# arp32_control register map
Vendor: Texas Instruments
Peripheral module from a debugger description file (folder ihwa).
Registers are 32-bit, access not given, no defined reset value unless marked. A register's access mark holds for its fields unless they carry their own. Offsets are as the file gives them; lines under a group give offsets from that group; [hi:lo] are bit positions; {n}, {i} and the like mark numbered series; 'fields as' and 'values as' point back to an identical list; <NAME> marks a mode.

## Control — Control Registers
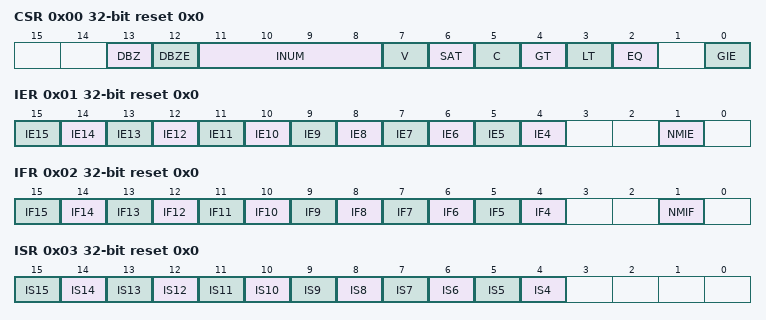
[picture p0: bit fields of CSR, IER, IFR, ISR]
0x00 CSR rw reset 0x0 — Control Status Register
  [13] DBZ — Divide by Zero
  [12] DBZE — Divide by Zero Enable
  [11:8] INUM — Interrupt Number
  [7] V — Overflow Bit
  [6] SAT — Saturation Bit
  [5] C — Carry Bit
  [4] GT — Greater Than Bit
  [3] LT — Less Than Bit
  [2] EQ — Equal Bit
  [0] GIE — Global Interrupt Enable
0x01 IER rw reset 0x0 — Interrupt Enable Register
  [n] IE{n} (n=4..15) — Enable Bit for INT{n}
  [1] NMIE — Enable Bit for NMI
0x02 IFR rw reset 0x0 — Interrupt Flag Register
  [n] IF{n} (n=4..15) — Flag Bit for INT{n}
  [1] NMIF — Flag Bit for NMI
0x03 ISR wo reset 0x0 — Interrupt Set Register
  [n] IS{n} (n=4..15) — Set Bit for INT{n}
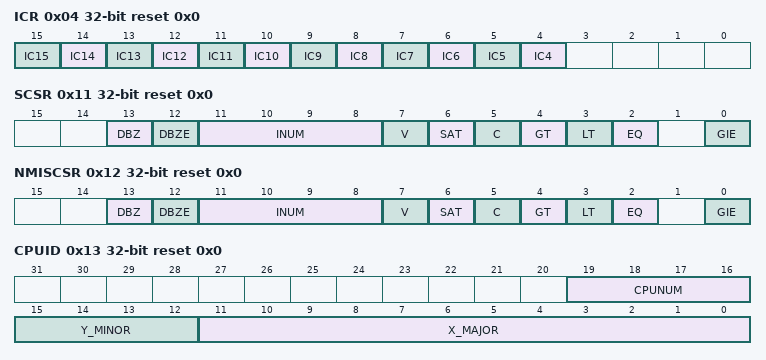
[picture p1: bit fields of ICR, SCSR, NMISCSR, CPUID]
0x04 ICR wo reset 0x0 — Interrupt Clear Register
  [n] IC{n} (n=4..15) — Clear Bit for INT{n}
0x05 NRP — NMI Return Pointer (half word address)
0x06 IRP — Interrupt Return Pointer (half word address)
0x07 SP — Stack Pointer (byte address)
0x08 GDP — Global Data Pointer (byte address)
0x09 LR — Link Register (half word address)
0x0A LSA0 — Loop 0 Start Address (byte address)
0x0B LEA0 — Loop 0 End Address (byte address)
0x0C LCNT0 — Loop 0 Iteration Count
0x0D LSA1 — Loop 1 Start Address (byte address)
0x0E LEA1 — Loop 1 End Address (byte address)
0x0F LCNT1 — Loop 1 Iteration Count
0x10 LCNT0RLD — Loop 0 Iteration Count Reload Value
0x11 SCSR rw reset 0x0 — Shadow CSR
  [13] DBZ — Shadow Copy of CSR:DBZ
  [12] DBZE — Shadow Copy of CSR:DBZE
  [11:8] INUM — Shadow Copy of CSR:INUM
  [7] V — Shadow Copy of CSR:V
  [6] SAT — Shadow Copy of CSR:SAT
  [5] C — Shadow Copy of CSR:C
  [4] GT — Shadow Copy of CSR:GT
  [3] LT — Shadow Copy of CSR:LT
  [2] EQ — Shadow Copy of CSR:EQ
  [0] GIE — Shadow Copy of CSR:GIE
0x12 NMISCSR rw reset 0x0 — NMI Shadow CSR
  fields as SCSR
0x13 CPUID ro reset 0x0
  [19:16] CPUNUM — CPU Instance Identifier
  [15:12] Y_MINOR — Minor Version Number
  [11:0] X_MAJOR — Major Version Number
0x14 DPC — Decode Program Counter (half word address)
0x15 TSCL — Time Stamp Counter Low Half
0x16 TSCH — Time Stamp Counter High Half
